# M55M1 register map
File version: 1.0
Registers are 32-bit, read-write, reset 0x0 unless marked. A register's access mark holds for its fields unless they carry their own. Offsets are from the block's base; [hi:lo] are bit positions.

## SCS — SCR Register Map
Base 0xE000E000
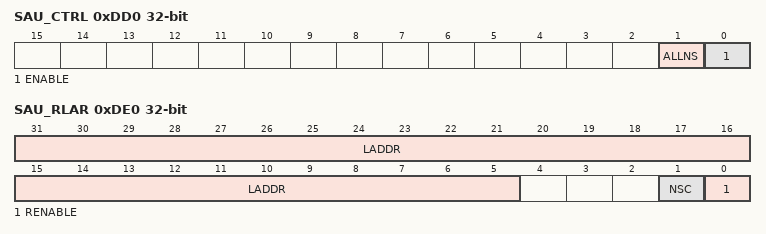
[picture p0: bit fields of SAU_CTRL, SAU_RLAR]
0xDD0 SAU_CTRL — SAU Control Register
  [1] ALLNS — All Non-secure
    0=All Memory region is marked as Secure and is not Non-secure callable; 1=All Memory region is marked as Non-secure by SAU, indicating the security attribute of all memory is defined by IDAU
  [0] ENABLE — SAU Enable Bit
    0=SAU Disabled; 1=SAU Enabled
0xDD4 SAU_TYPE ro reset 0x8
  [7:0] SREGION — SAU Regions. Indicates the number of regions implemented by the Security Attribution Unit.
0xDD8 SAU_RNR (reset mask 0xFFFFFF00) — SAU Region Number Register
  [7:0] REGION — Current Region of SAU. Indicates the SAU region accessed by SAU_RBAR and SAU_RLAR. Set a value to select the region to be configure through SAU_RBAR and SAU_RLAR. It can be set to 0 ~ the value of SAU_TYPE -1.
0xDDC SAU_RBAR (reset mask 0xF) — SAU Region Base Address Register
  [31:5] BADDR — Base Address of Currently Selected Region. The base address of the region selected by SAU_RNR. SAU region is 32-byte-aligned.
0xDE0 SAU_RLAR — SAU Region Limit Address Register
  [31:5] LADDR — Limit Address of Currently Selected Region. The limited address of the region selected by SAU_RNR. The region of the selected SAU region is [SAU_RBAR.BADDR,5'b00000] ~ [LADDR,5'b11111]
  [1] NSC — Non-secure Callable Setting Bit. Controls whether Non-secure state is permitted to execute an SG instruction from this region.
    0=Region is not Non-secure callable. If RENABLE =1, the current region is Non-secure; 1=Region is Non-secure callable. If RENABLE=1, the current region is Secure and Non-secure callable
  [0] RENABLE — Region Enable Bit. Enable or disable the currently selected region set by SAU_RNR.
    0=Disabled selected region set by SAU_RNR; 1=Enabled selected region set by SAU_RNR

## FVC — SCU Register Map
Base 0x40402500
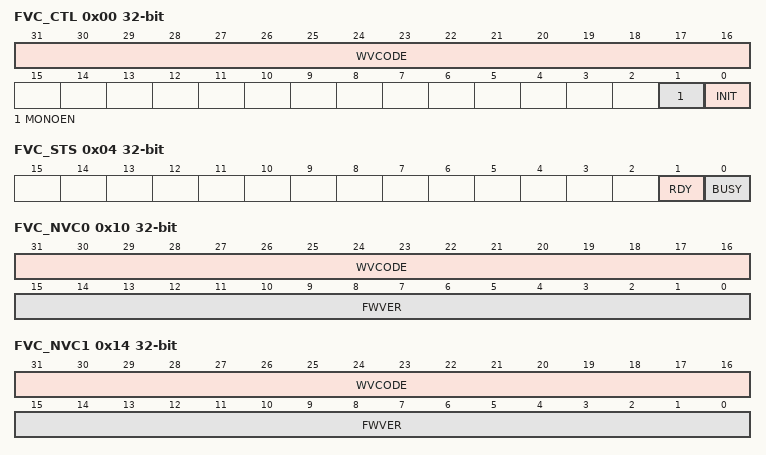
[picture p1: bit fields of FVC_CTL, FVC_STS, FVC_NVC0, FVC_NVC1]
0x00 FVC_CTL (reset mask 0xFFFFFFF0) — FVC Control Register
  [31:16] WVCODE — Verification Code. When written, this field must be 0x7710
  [1] MONOEN — Monotonic Enable Bit. Set to 1 to enable the monotonic mechanism of FVC. Note: This bit can be set to1 but cannot be cleared to 0.
  [0] INIT — FVC Init Bit. Set to 1 to enable FVC. This bit is writable when FVC is at Reset state. Note: After set to 1, this bit is cleared to 0 automatically when FVC is back to Reset state.
0x04 FVC_STS ro (reset mask 0xFFFFFFF0) — FVC Status Register
  [1] RDY — FVC Ready Bit. Indicates the FVC is ready after the initial process.
  [0] BUSY — FVC Busy Bit. Indicates the FVC is at busy state.
0x10 FVC_NVC0 (reset mask 0xFFFF0000) — Non-volatile Version Counter Control Register0
  [31:16] WVCODE — Verification Code. When written, this field must be the current firmware version number of NVC0
  [15:0] FWVER — Firmware Version. Read: Indicates the current firmware version of NVC0. Write: Updates the firmware version of NVC0. The maximum value of this field is 63.
0x14 FVC_NVC1 (reset mask 0xFFFF0000) — Non-volatile Version Counter Control Register1
  [31:16] WVCODE — Verification Code. When written, this field must be the current firmware version number of NVC1
  [15:0] FWVER — Firmware Version. Read: Indicates the current firmware version of NVC1. Write: Updates the firmware version of NVC1. The maximum value of this field is 63.
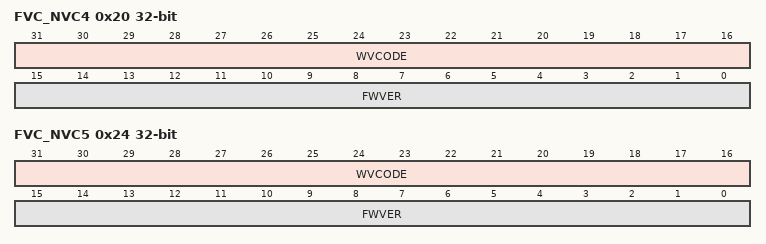
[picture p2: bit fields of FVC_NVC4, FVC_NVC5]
0x20 FVC_NVC4 (reset mask 0xFFFF0000) — Non-volatile Version Counter Control Register4
  [31:16] WVCODE — Verification Code. When written, this field must be the current firmware version number of NVC4
  [15:0] FWVER — Firmware Version. Read: Indicates the current firmware version of NVC4. Write: Updates the firmware version of NVC4. The maximum value of this field is 255.
0x24 FVC_NVC5 (reset mask 0xFFFF0000) — Non-volatile Version Counter Control Register5
  [31:16] WVCODE — Verification Code. When written, this field must be the current firmware version number of NVC5
  [15:0] FWVER — Firmware Version. Read: Indicates the current firmware version of NVC5. Write: Updates the firmware version of NVC5. The maximum value of this field is 255.
